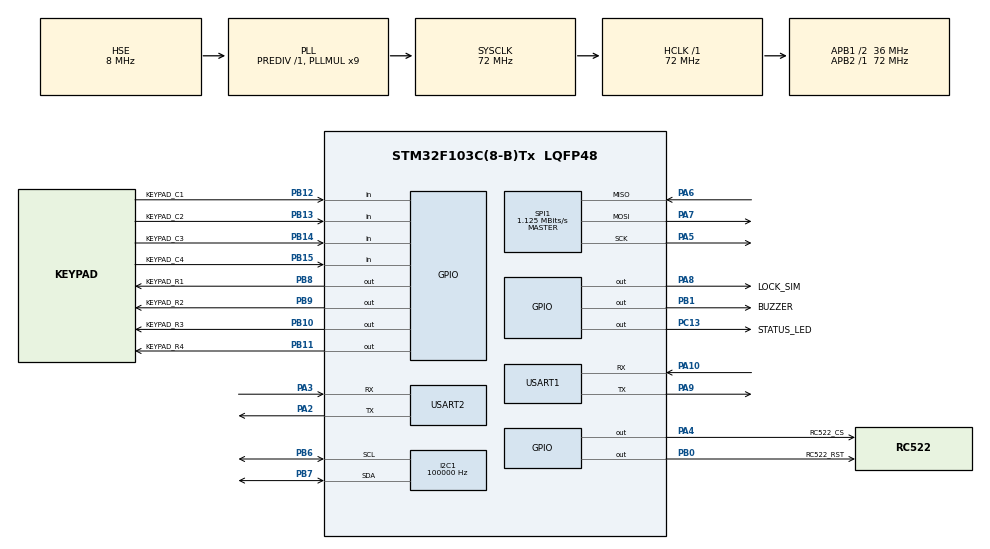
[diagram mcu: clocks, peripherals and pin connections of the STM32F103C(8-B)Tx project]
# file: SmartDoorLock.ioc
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Mcu.Family=STM32F1
I2C1.ClockSpeed=100000
Mcu.Name=STM32F103C(8-B)Tx
Mcu.Package=LQFP48
NVIC.PriorityGroup=NVIC_PRIORITYGROUP_4
NVIC.USART2_IRQn=true\:5\:0\:false\:false\:true\:true\:true\:true
PA10.Mode=Asynchronous
PA10.Signal=USART1_RX
PA2.Mode=Asynchronous
PA2.Signal=USART2_TX
PA3.Mode=Asynchronous
PA3.Signal=USART2_RX
PA13.Mode=Serial_Wire
PA13.Signal=SYS_JTMS-SWDIO
PA14.Mode=Serial_Wire
PA14.Signal=SYS_JTCK-SWCLK
PA4.GPIO_Label=RC522_CS
PA4.PinState=GPIO_PIN_SET
PA4.Signal=GPIO_Output
PA5.Mode=Full_Duplex_Master
PA5.Signal=SPI1_SCK
PA6.Mode=Full_Duplex_Master
PA6.Signal=SPI1_MISO
PA7.Mode=Full_Duplex_Master
PA7.Signal=SPI1_MOSI
PA8.GPIO_Label=LOCK_SIM
PA8.PinState=GPIO_PIN_RESET
PA8.Signal=GPIO_Output
PA9.Mode=Asynchronous
PA9.Signal=USART1_TX
PB6.Mode=I2C
PB6.Signal=I2C1_SCL
PB7.Mode=I2C
PB7.Signal=I2C1_SDA
PB8.GPIO_Label=KEYPAD_R1
PB8.PinState=GPIO_PIN_SET
PB8.Signal=GPIO_Output
PB9.GPIO_Label=KEYPAD_R2
PB9.PinState=GPIO_PIN_SET
PB9.Signal=GPIO_Output
PB10.GPIO_Label=KEYPAD_R3
PB10.PinState=GPIO_PIN_SET
PB10.Signal=GPIO_Output
PB11.GPIO_Label=KEYPAD_R4
PB11.PinState=GPIO_PIN_SET
PB11.Signal=GPIO_Output
PB12.GPIO_Label=KEYPAD_C1
PB12.GPIO_PuPd=GPIO_PULLUP
PB12.Signal=GPIO_Input
PB13.GPIO_Label=KEYPAD_C2
PB13.GPIO_PuPd=GPIO_PULLUP
PB13.Signal=GPIO_Input
PB14.GPIO_Label=KEYPAD_C3
PB14.GPIO_PuPd=GPIO_PULLUP
PB14.Signal=GPIO_Input
PB15.GPIO_Label=KEYPAD_C4
PB15.GPIO_PuPd=GPIO_PULLUP
PB15.Signal=GPIO_Input
PB0.GPIO_Label=RC522_RST
PB0.PinState=GPIO_PIN_RESET
PB0.Signal=GPIO_Output
PB1.GPIO_Label=BUZZER
PB1.PinState=GPIO_PIN_RESET
PB1.Signal=GPIO_Output
PC13-TAMPER-RTC.GPIO_Label=STATUS_LED
PC13-TAMPER-RTC.PinState=GPIO_PIN_SET
PC13-TAMPER-RTC.Signal=GPIO_Output
PD0-OSC_IN.Mode=HSE-External-Oscillator
PD0-OSC_IN.Signal=RCC_OSC_IN
PD1-OSC_OUT.Mode=HSE-External-Oscillator
PD1-OSC_OUT.Signal=RCC_OSC_OUT
ProjectManager.HeapSize=0x200
ProjectManager.StackSize=0x400
ProjectManager.TargetToolchain=MDK-ARM V5.32
RCC.AHBFreq_Value=72000000
RCC.APB1CLKDivider=RCC_HCLK_DIV2
RCC.APB1Freq_Value=36000000
RCC.APB1TimFreq_Value=72000000
RCC.APB2Freq_Value=72000000
RCC.APB2TimFreq_Value=72000000
RCC.HCLKFreq_Value=72000000
RCC.PLLMUL=RCC_PLL_MUL9
RCC.PLLSourceVirtual=RCC_PLLSOURCE_HSE
RCC.SYSCLKFreq_VALUE=72000000
RCC.SYSCLKSource=RCC_SYSCLKSOURCE_PLLCLK
RCC.USBFreq_Value=72000000
SPI1.BaudRatePrescaler=SPI_BAUDRATEPRESCALER_64
SPI1.CalculateBaudRate=1.125 MBits/s
SPI1.Direction=SPI_DIRECTION_2LINES
SPI1.Mode=SPI_MODE_MASTER
SPI1.VirtualType=VM_MASTER
USART1.VirtualMode=VM_ASYNC
USART2.VirtualMode=VM_ASYNC
VP_IWDG_VS_IWDG.Mode=IWDG_Activate
board=custom

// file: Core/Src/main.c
/* USER CODE BEGIN Header */
/**
  ******************************************************************************
  * @file           : main.c
  * @brief          : Main program body
  ******************************************************************************
  * @attention
  *
  * Copyright (c) 2026 STMicroelectronics.
  * All rights reserved.
  *
  * This software is licensed under terms that can be found in the LICENSE file
  * in the root directory of this software component.
  * If no LICENSE file comes with this software, it is provided AS-IS.
  *
  ******************************************************************************
  */
/* USER CODE END Header */
#include "main.h"
#include "i2c.h"
#include "spi.h"
#include "usart.h"
#include "gpio.h"
#include "iwdg.h"

/* USER CODE BEGIN Includes */
#include "app.h"

/* USER CODE END Includes */

void SystemClock_Config(void);

/* USER CODE BEGIN 0 */
/**
 * @brief 本项目的主循环入口说明。
 * @details 外设初始化顺序以 GPIO 安全输出为先；应用任务采用状态机小步执行，独立看门狗
 *          仅在主循环持续运行时喂狗。PA13、PA14 未参与任何业务 GPIO 配置，保留 SWD。
 * @version 0.1.0
 * @date    2026-10-05
 * 关联需求：REQ-APP-001、REQ-SEC-001。
 * 关联设计：DES-CORE-001。
 */

/* USER CODE END 0 */

int main(void)
{

  /* MCU Configuration--------------------------------------------------------*/

  /* Reset of all peripherals, Initializes the Flash interface and the Systick. */
  HAL_Init();

  /* Configure the system clock */
  SystemClock_Config();

  /*
   * GPIO 必须最先初始化：其中已预置门锁模拟、RC522 片选等安全电平，
   * 防止其他外设初始化期间输出悬空或误动作。
   */
  MX_GPIO_Init();
  MX_USART1_UART_Init();
  MX_USART2_UART_Init();
  MX_I2C1_Init();
  MX_SPI1_Init();
  /* USER CODE BEGIN 2 */
  /* 应用初始化只建立服务关系；门锁仍由 GPIO 初始安全电平保持锁定。 */
  App_Init();
  /* 最后开启 IWDG，确保前面的初始化失败不会被不恰当地掩盖。 */
  MX_IWDG_Init();
  /* USER CODE END 2 */

  /* Infinite loop */
  while (1)
  {

    /* USER CODE BEGIN 3 */
    /* 禁止在此处加入 HAL_Delay()，各业务均通过 App_Task() 的状态机推进。 */
    App_Task();
    /* 只有主循环仍能完整运行时才刷新看门狗。 */
    Iwdg_Refresh();
  }
  /* USER CODE END 3 */
}

void SystemClock_Config(void)
{
  RCC_OscInitTypeDef RCC_OscInitStruct = {0};
  RCC_ClkInitTypeDef RCC_ClkInitStruct = {0};

  /** Initializes the RCC Oscillators according to the specified parameters
  * in the RCC_OscInitTypeDef structure.
  */
  RCC_OscInitStruct.OscillatorType = RCC_OSCILLATORTYPE_HSE;
  RCC_OscInitStruct.HSEState = RCC_HSE_ON;
  RCC_OscInitStruct.HSEPredivValue = RCC_HSE_PREDIV_DIV1;
  RCC_OscInitStruct.HSIState = RCC_HSI_ON;
  RCC_OscInitStruct.PLL.PLLState = RCC_PLL_ON;
  RCC_OscInitStruct.PLL.PLLSource = RCC_PLLSOURCE_HSE;
  RCC_OscInitStruct.PLL.PLLMUL = RCC_PLL_MUL9;
  if (HAL_RCC_OscConfig(&RCC_OscInitStruct) != HAL_OK)
  {
    Error_Handler();
  }

  /** Initializes the CPU, AHB and APB buses clocks
  */
  RCC_ClkInitStruct.ClockType = RCC_CLOCKTYPE_HCLK|RCC_CLOCKTYPE_SYSCLK
                              |RCC_CLOCKTYPE_PCLK1|RCC_CLOCKTYPE_PCLK2;
  RCC_ClkInitStruct.SYSCLKSource = RCC_SYSCLKSOURCE_PLLCLK;
  RCC_ClkInitStruct.AHBCLKDivider = RCC_SYSCLK_DIV1;
  RCC_ClkInitStruct.APB1CLKDivider = RCC_HCLK_DIV2;
  RCC_ClkInitStruct.APB2CLKDivider = RCC_HCLK_DIV1;

  if (HAL_RCC_ClockConfig(&RCC_ClkInitStruct, FLASH_LATENCY_2) != HAL_OK)
  {
    Error_Handler();
  }
}

__NO_RETURN void Error_Handler(void)
{
  /* USER CODE BEGIN Error_Handler_Debug */
  /* 时钟或 HAL 初始化失败后停止业务，门锁输出已在 GPIO 初始化前后维持安全状态。 */
  __disable_irq();
  while (1)
  {
  }
  /* USER CODE END Error_Handler_Debug */
}
